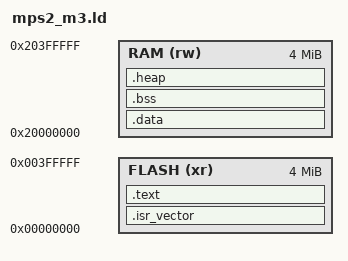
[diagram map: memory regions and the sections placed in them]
/*
 * FreeRTOS V202212.01
 * Copyright (C) 2020 Amazon.com, Inc. or its affiliates.  All Rights Reserved.
 *
 * Permission is hereby granted, free of charge, to any person obtaining a copy of
 * this software and associated documentation files (the "Software"), to deal in
 * the Software without restriction, including without limitation the rights to
 * use, copy, modify, merge, publish, distribute, sublicense, and/or sell copies of
 * the Software, and to permit persons to whom the Software is furnished to do so,
 * subject to the following conditions:
 *
 * The above copyright notice and this permission notice shall be included in all
 * copies or substantial portions of the Software.
 *
 * THE SOFTWARE IS PROVIDED "AS IS", WITHOUT WARRANTY OF ANY KIND, EXPRESS OR
 * IMPLIED, INCLUDING BUT NOT LIMITED TO THE WARRANTIES OF MERCHANTABILITY, FITNESS
 * FOR A PARTICULAR PURPOSE AND NONINFRINGEMENT. IN NO EVENT SHALL THE AUTHORS OR
 * COPYRIGHT HOLDERS BE LIABLE FOR ANY CLAIM, DAMAGES OR OTHER LIABILITY, WHETHER
 * IN AN ACTION OF CONTRACT, TORT OR OTHERWISE, ARISING FROM, OUT OF OR IN
 * CONNECTION WITH THE SOFTWARE OR THE USE OR OTHER DEALINGS IN THE SOFTWARE.
 *
 * https://www.FreeRTOS.org
 * https://github.com/FreeRTOS
 *
 */

MEMORY
{
    FLASH (xr) : ORIGIN = 0x00000000, LENGTH = 4M /* to 0x00003FFF = 0x007FFFFF*/
    RAM (rw)  : ORIGIN = 0x20000000, LENGTH = 4M /* to 0x21FFFFFF = 0xFFFFFF */
}
ENTRY(Reset_Handler)

_Min_Heap_Size = 0x8 ;        /* Not used as building heap_4.c */
_Min_Stack_Size = 0x400 ;       /* Required amount of stack.  Used by main(), then re-used as the interrupt stack after the kernel starts. */
_estack = ORIGIN(RAM) + LENGTH(RAM);


SECTIONS
{
    .isr_vector :
    {
        __vector_table = .;
        KEEP(*(.isr_vector))
        . = ALIGN(4);
    } > FLASH

    .text :
    {
        *(.text)
        *(.rodata*)
        *(.constdata*)
        _etext = .;
        _sidata = .;
    } > FLASH

    .data :
    {
        . = ALIGN(8);
        _data = .;
        _sdata = .;
        *(vtable)
        *(.data)
        _edata = .;
    } > RAM

    .bss :
    {
        . = ALIGN(8);
        _bss = .;
        _sbss = .;
        *(.bss)
        _ebss = .;
    } > RAM

    .heap :
    {
        . = ALIGN(8);
        PROVIDE ( end = . );
        PROVIDE ( _end = . );
        _heap_bottom = .;
        . = . + _Min_Heap_Size;
        _heap_top = .;
        . = . + _Min_Stack_Size;
        . = ALIGN(8);
   } >RAM

   /* Set stack top to end of RAM, and stack limit move down by
    * size of stack_dummy section */
   __StackTop = ORIGIN(RAM) + LENGTH(RAM);
   __StackLimit = __StackTop - _Min_Stack_Size;
   PROVIDE(__stack = __StackTop);

  /* Check if data + heap + stack exceeds RAM limit */
  ASSERT(__StackLimit >= _heap_top, "region RAM overflowed with stack")

}
